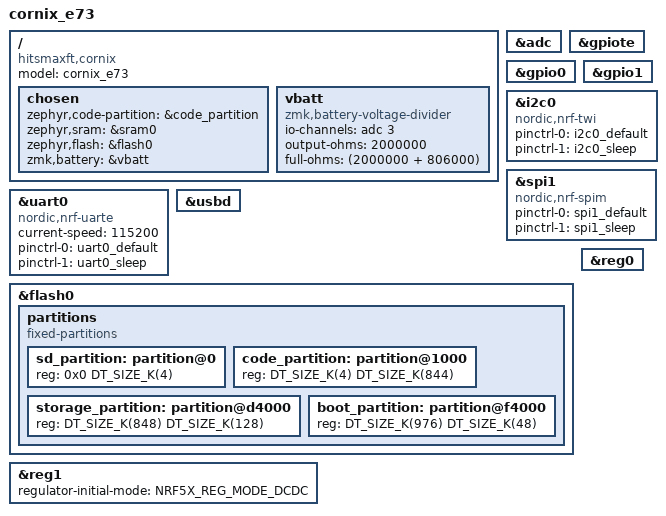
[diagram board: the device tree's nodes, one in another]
/ {
    model = "cornix_e73";
    compatible = "hitsmaxft,cornix";

    chosen {
        zephyr,code-partition = &code_partition;
        zephyr,sram = &sram0;
        zephyr,flash = &flash0;
        zmk,battery = &vbatt;
    };

    vbatt: vbatt {
        compatible = "zmk,battery-voltage-divider";
        io-channels = <&adc 3>;
        output-ohms = <2000000>;
        full-ohms = <(2000000 + 806000)>;
    };
};

&adc {
    status = "okay";
};

&gpiote {
    status = "okay";
};

&gpio0 {
    status = "okay";
};

&gpio1 {
    status = "okay";
};

&i2c0 {
    compatible = "nordic,nrf-twi";
    pinctrl-0 = <&i2c0_default>;
    pinctrl-1 = <&i2c0_sleep>;
    pinctrl-names = "default", "sleep";
};

&spi1 {
    compatible = "nordic,nrf-spim";
    pinctrl-0 = <&spi1_default>;
    pinctrl-1 = <&spi1_sleep>;
    pinctrl-names = "default", "sleep";
};

&uart0 {
    compatible = "nordic,nrf-uarte";
    current-speed = <115200>;
    pinctrl-0 = <&uart0_default>;
    pinctrl-1 = <&uart0_sleep>;
    pinctrl-names = "default", "sleep";
};

zephyr_udc0: &usbd {
    status = "okay";
};

&flash0 {
    partitions {
        compatible = "fixed-partitions";
        #address-cells = <1>;
        #size-cells = <1>;
        sd_partition: partition@0 {
            reg = <0x0 DT_SIZE_K(4)>;
        };

        code_partition: partition@1000 {
            reg = <DT_SIZE_K(4) DT_SIZE_K(844)>;
        };

        /*
         * The flash starting at 0x000d4000 and ending at
         * 0x000f3fff is reserved for use by the application.
         * It will be used by FCB/LittleFS/NVS if enabled.
         */
        storage_partition: partition@d4000 {
            reg = <DT_SIZE_K(848) DT_SIZE_K(128)>;
        };

        boot_partition: partition@f4000 {
            reg = <DT_SIZE_K(976) DT_SIZE_K(48)>;
        };
    };
};

/*
 * DC/DC converters (added 2026-09-21). The stock RMK firmware for this board
 * (rmk-cornix keyboard.toml: dcdc_reg0 = true, dcdc_reg1 = true,
 * dcdc_reg0_voltage = "3V3") runs both nRF52840 regulators in DC/DC mode;
 * Zephyr defaults to LDO mode. DC/DC lowers current draw and supply droop
 * during radio bursts. The E73 module carries the DCC/DCCH inductors, and
 * REG0 (high-voltage mode, VDDH = battery/USB) outputs 3.3 V as programmed in
 * UICR.REGOUT0 by the original firmware.
 */
#include <zephyr/dt-bindings/regulator/nrf5x.h>

/* REG0 (HV stage) has no mode property in Zephyr 4.1: enabling the node turns
 * on the high-voltage DC/DC stage (same as nrf52840dk). */
&reg0 {
    status = "okay";
};

&reg1 {
    regulator-initial-mode = <NRF5X_REG_MODE_DCDC>;
};
